AUTOSAR XML (schema 00044)
package /E40_Platform_System_SystemPackage/Components
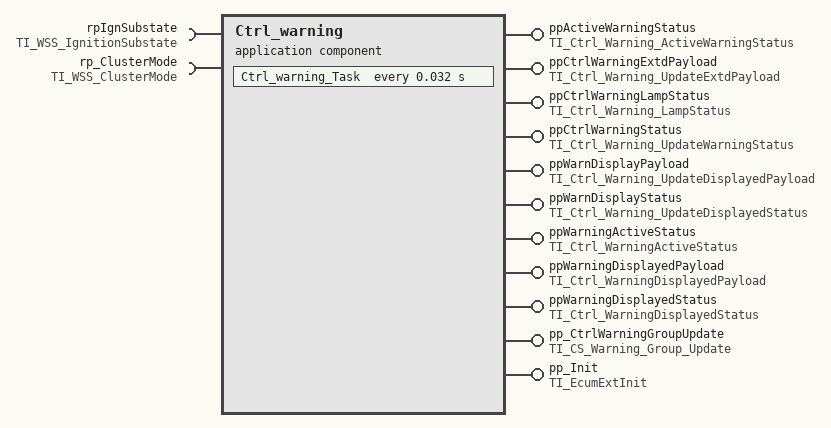
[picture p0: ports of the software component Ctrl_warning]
  application sw component type Ctrl_warning
    11 x provide port:
      ppActiveWarningStatus: server-com-spec{operation=GetActiveWarningStatus, queue-length=1}, provided-interface=TI_Ctrl_Warning_ActiveWarningStatus
      ppCtrlWarningExtdPayload: server-com-spec{operation=UpdateExtdPayload, queue-length=1}, provided-interface=TI_Ctrl_Warning_UpdateExtdPayload
      ppCtrlWarningLampStatus: provided-interface=TI_Ctrl_Warning_LampStatus
        provided-com-specs:
          operation=Get_Red_MasterLamp_Status, queue-length=1
          operation=Get_Yellow_MasterLamp_Status, queue-length=1
      ppCtrlWarningStatus: server-com-spec{operation=UpdateWarningStatus, queue-length=1}, provided-interface=TI_Ctrl_Warning_UpdateWarningStatus
      ppWarnDisplayPayload: server-com-spec{operation=SetWarningDisplayedPayload, queue-length=1}, provided-interface=TI_Ctrl_Warning_UpdateDisplayedPayload
      ppWarnDisplayStatus: server-com-spec{operation=SetWarningDisplayedStatus, queue-length=1}, provided-interface=TI_Ctrl_Warning_UpdateDisplayedStatus
      ppWarningActiveStatus: server-com-spec{operation=GetWarningActiveStatus, queue-length=1}, provided-interface=TI_Ctrl_WarningActiveStatus
      ppWarningDisplayedPayload: server-com-spec{operation=GetWarningDisplayedPayload, queue-length=1}, provided-interface=TI_Ctrl_WarningDisplayedPayload
      ppWarningDisplayedStatus: server-com-spec{operation=GetWarningDisplayedStatus, queue-length=1}, provided-interface=TI_Ctrl_WarningDisplayedStatus
      pp_CtrlWarningGroupUpdate: server-com-spec{operation=Warning_Group_update, queue-length=1}, provided-interface=TI_CS_Warning_Group_Update
      pp_Init: server-com-spec{operation=Init, queue-length=1}, provided-interface=TI_EcumExtInit
    require port rpIgnSubstate: nonqueued-receiver-com-spec{data-element=IgnitionSubstate, init-value=constant-reference=Ctrl_warningIgnitionSubstateValue0}, required-interface=TI_WSS_IgnitionSubstate
    require port rp_ClusterMode: nonqueued-receiver-com-spec{data-element=WSSCurrentClusterMode, init-value=constant-reference=Ctrl_warningWSSCurrentClusterModeValue0}, required-interface=TI_WSS_ClusterMode
    behavior IB_Ctrl_warning
      9 x operation invoked event:
        OIE_ppActiveWarningStatus_Ctrl_warning_GetActiveWarningStatusTrigByGetActiveWarningStatus: start-on-event=Ctrl_warning_GetActiveWarningStatus, operation=ppActiveWarningStatus.GetActiveWarningStatus
        OIE_ppWarningActiveStatus_Ctrl_warning_GetWarningActiveStatusTrigByGetWarningActiveStatus: start-on-event=Ctrl_warning_GetWarningActiveStatus, operation=ppWarningActiveStatus.GetWarningActiveStatus
        OIE_ppWarningDisplayedPayload_Ctrl_warning_GetWarningDisplayedPayloadTrigByGetWarningDisplayedPayload: start-on-event=Ctrl_warning_GetWarningDisplayedPayload, operation=ppWarningDisplayedPayload.GetWarningDisplayedPayload
        OIE_ppWarningDisplayedStatus_Ctrl_warning_GetWarningDisplayedStatusTrigByGetWarningDisplayedStatus: start-on-event=Ctrl_warning_GetWarningDisplayedStatus, operation=ppWarningDisplayedStatus.GetWarningDisplayedStatus
        OIE_ppCtrlWarningLampStatus_Ctrl_warning_Get_Red_MasterLamp_StatusTrigByGet_Red_MasterLamp_Status: start-on-event=Ctrl_warning_Get_Red_MasterLamp_Status, operation=ppCtrlWarningLampStatus.Get_Red_MasterLamp_Status
        OIE_ppCtrlWarningLampStatus_Ctrl_warning_Get_Yellow_MasterLamp_StatusTrigByGet_Yellow_MasterLamp_Status: start-on-event=Ctrl_warning_Get_Yellow_MasterLamp_Status, operation=ppCtrlWarningLampStatus.Get_Yellow_MasterLamp_Status
        OIE_pp_Init_Ctrl_warning_InitTrigByInit: start-on-event=Ctrl_warning_Init, operation=pp_Init.Init
        OIE_ppWarnDisplayPayload_Ctrl_warning_SetWarningDisplayedPayloadTrigBySetWarningDisplayedPayload: start-on-event=Ctrl_warning_SetWarningDisplayedPayload, operation=ppWarnDisplayPayload.SetWarningDisplayedPayload
        OIE_ppWarnDisplayStatus_Ctrl_warning_SetWarningDisplayedStatusTrigBySetWarningDisplayedStatus: start-on-event=Ctrl_warning_SetWarningDisplayedStatus, operation=ppWarnDisplayStatus.SetWarningDisplayedStatus
      timing event TECtrl_warning_Task: start-on-event=Ctrl_warning_Task, period=0.032
      operation invoked event OIE_ppCtrlWarningExtdPayload_Ctrl_warning_UpdateExtdPayloadTrigByUpdateExtdPayload: start-on-event=Ctrl_warning_UpdateExtdPayload, operation=ppCtrlWarningExtdPayload.UpdateExtdPayload
      operation invoked event OIE_ppCtrlWarningStatus_Ctrl_warning_UpdateWarningStatusTrigByUpdateWarningStatus: start-on-event=Ctrl_warning_UpdateWarningStatus, operation=ppCtrlWarningStatus.UpdateWarningStatus
      operation invoked event OIE_pp_CtrlWarningGroupUpdate_Ctrl_warning_Warning_Group_updateTrigByWarning_Group_update: start-on-event=Ctrl_warning_Warning_Group_update, operation=pp_CtrlWarningGroupUpdate.Warning_Group_update
      port-api-options:
        enable-take-address=false, indirect-api=false, port=ppActiveWarningStatus
        enable-take-address=false, indirect-api=false, port=ppCtrlWarningExtdPayload
        enable-take-address=false, indirect-api=false, port=ppCtrlWarningLampStatus
        enable-take-address=false, indirect-api=false, port=ppCtrlWarningStatus
        enable-take-address=false, indirect-api=false, port=ppWarnDisplayPayload
        enable-take-address=false, indirect-api=false, port=ppWarnDisplayStatus
        enable-take-address=false, indirect-api=false, port=ppWarningActiveStatus
        enable-take-address=false, indirect-api=false, port=ppWarningDisplayedPayload
        enable-take-address=false, indirect-api=false, port=ppWarningDisplayedStatus
        enable-take-address=false, indirect-api=false, port=pp_CtrlWarningGroupUpdate
        enable-take-address=false, indirect-api=false, port=pp_Init
        enable-take-address=false, indirect-api=false, port=rpIgnSubstate
        enable-take-address=false, indirect-api=false, port=rp_ClusterMode
      13 x runnable, all with can-be-invoked-concurrently=true:
        Ctrl_warning_GetActiveWarningStatus
        Ctrl_warning_GetWarningActiveStatus
        Ctrl_warning_GetWarningDisplayedPayload
        Ctrl_warning_GetWarningDisplayedStatus
        Ctrl_warning_Get_Red_MasterLamp_Status
        Ctrl_warning_Get_Yellow_MasterLamp_Status
        Ctrl_warning_Init
        Ctrl_warning_SetWarningDisplayedPayload
        Ctrl_warning_SetWarningDisplayedStatus
        Ctrl_warning_Task
          data-receive-point-by-arguments:
            access DRA_rpIgnSubstate_IgnitionSubstate: accessed-variable=rpIgnSubstate.IgnitionSubstate
            access DRA_rp_ClusterMode_WSSCurrentClusterMode: accessed-variable=rp_ClusterMode.WSSCurrentClusterMode
        Ctrl_warning_UpdateExtdPayload
        Ctrl_warning_UpdateWarningStatus
        Ctrl_warning_Warning_Group_update
  swc implementation IMPL_Ctrl_warning: behavior=IB_Ctrl_warning
